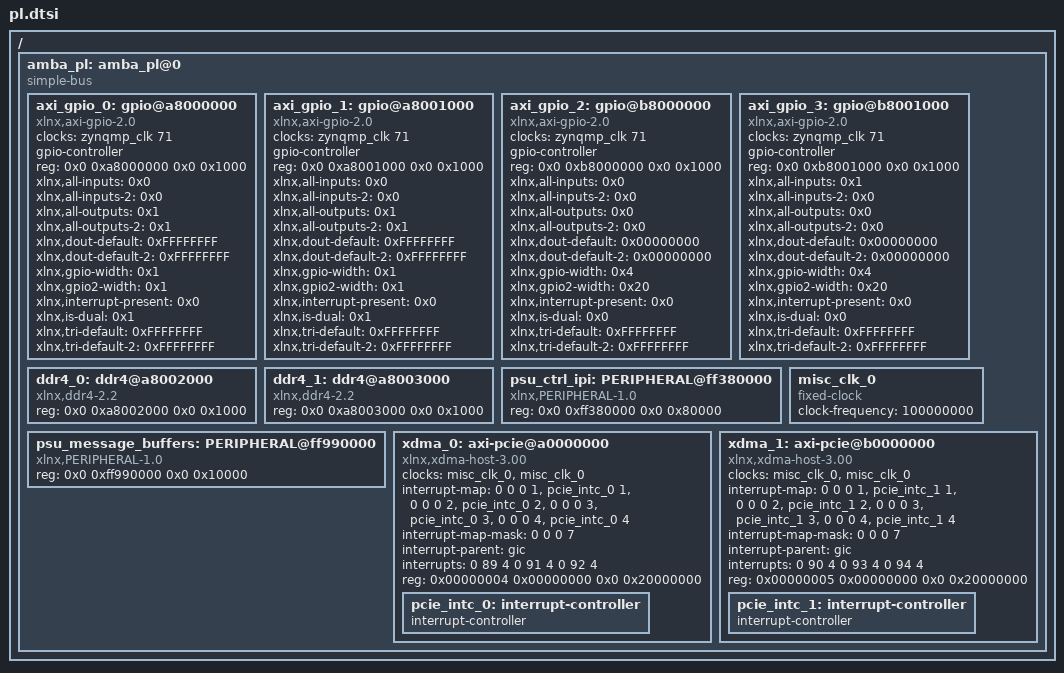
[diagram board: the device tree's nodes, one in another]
/*
 * CAUTION: This file is automatically generated by Xilinx.
 * Version:  
 * Today is: Wed Dec 14 13:36:20 2022
 */


/ {
	amba_pl: amba_pl@0 {
		#address-cells = <2>;
		#size-cells = <2>;
		compatible = "simple-bus";
		ranges ;
		axi_gpio_0: gpio@a8000000 {
			#gpio-cells = <3>;
			clock-names = "s_axi_aclk";
			clocks = <&zynqmp_clk 71>;
			compatible = "xlnx,axi-gpio-2.0", "xlnx,xps-gpio-1.00.a";
			gpio-controller ;
			reg = <0x0 0xa8000000 0x0 0x1000>;
			xlnx,all-inputs = <0x0>;
			xlnx,all-inputs-2 = <0x0>;
			xlnx,all-outputs = <0x1>;
			xlnx,all-outputs-2 = <0x1>;
			xlnx,dout-default = <0xFFFFFFFF>;
			xlnx,dout-default-2 = <0xFFFFFFFF>;
			xlnx,gpio-width = <0x1>;
			xlnx,gpio2-width = <0x1>;
			xlnx,interrupt-present = <0x0>;
			xlnx,is-dual = <0x1>;
			xlnx,tri-default = <0xFFFFFFFF>;
			xlnx,tri-default-2 = <0xFFFFFFFF>;
		};
		axi_gpio_1: gpio@a8001000 {
			#gpio-cells = <3>;
			clock-names = "s_axi_aclk";
			clocks = <&zynqmp_clk 71>;
			compatible = "xlnx,axi-gpio-2.0", "xlnx,xps-gpio-1.00.a";
			gpio-controller ;
			reg = <0x0 0xa8001000 0x0 0x1000>;
			xlnx,all-inputs = <0x0>;
			xlnx,all-inputs-2 = <0x0>;
			xlnx,all-outputs = <0x1>;
			xlnx,all-outputs-2 = <0x1>;
			xlnx,dout-default = <0xFFFFFFFF>;
			xlnx,dout-default-2 = <0xFFFFFFFF>;
			xlnx,gpio-width = <0x1>;
			xlnx,gpio2-width = <0x1>;
			xlnx,interrupt-present = <0x0>;
			xlnx,is-dual = <0x1>;
			xlnx,tri-default = <0xFFFFFFFF>;
			xlnx,tri-default-2 = <0xFFFFFFFF>;
		};
		axi_gpio_2: gpio@b8000000 {
			#gpio-cells = <3>;
			clock-names = "s_axi_aclk";
			clocks = <&zynqmp_clk 71>;
			compatible = "xlnx,axi-gpio-2.0", "xlnx,xps-gpio-1.00.a";
			gpio-controller ;
			reg = <0x0 0xb8000000 0x0 0x1000>;
			xlnx,all-inputs = <0x0>;
			xlnx,all-inputs-2 = <0x0>;
			xlnx,all-outputs = <0x0>;
			xlnx,all-outputs-2 = <0x0>;
			xlnx,dout-default = <0x00000000>;
			xlnx,dout-default-2 = <0x00000000>;
			xlnx,gpio-width = <0x4>;
			xlnx,gpio2-width = <0x20>;
			xlnx,interrupt-present = <0x0>;
			xlnx,is-dual = <0x0>;
			xlnx,tri-default = <0xFFFFFFFF>;
			xlnx,tri-default-2 = <0xFFFFFFFF>;
		};
		axi_gpio_3: gpio@b8001000 {
			#gpio-cells = <3>;
			clock-names = "s_axi_aclk";
			clocks = <&zynqmp_clk 71>;
			compatible = "xlnx,axi-gpio-2.0", "xlnx,xps-gpio-1.00.a";
			gpio-controller ;
			reg = <0x0 0xb8001000 0x0 0x1000>;
			xlnx,all-inputs = <0x1>;
			xlnx,all-inputs-2 = <0x0>;
			xlnx,all-outputs = <0x0>;
			xlnx,all-outputs-2 = <0x0>;
			xlnx,dout-default = <0x00000000>;
			xlnx,dout-default-2 = <0x00000000>;
			xlnx,gpio-width = <0x4>;
			xlnx,gpio2-width = <0x20>;
			xlnx,interrupt-present = <0x0>;
			xlnx,is-dual = <0x0>;
			xlnx,tri-default = <0xFFFFFFFF>;
			xlnx,tri-default-2 = <0xFFFFFFFF>;
		};
		ddr4_0: ddr4@a8002000 {
			compatible = "xlnx,ddr4-2.2";
			reg = <0x0 0xa8002000 0x0 0x1000>;
		};
		ddr4_1: ddr4@a8003000 {
			compatible = "xlnx,ddr4-2.2";
			reg = <0x0 0xa8003000 0x0 0x1000>;
		};
		psu_ctrl_ipi: PERIPHERAL@ff380000 {
			compatible = "xlnx,PERIPHERAL-1.0";
			reg = <0x0 0xff380000 0x0 0x80000>;
		};
		psu_message_buffers: PERIPHERAL@ff990000 {
			compatible = "xlnx,PERIPHERAL-1.0";
			reg = <0x0 0xff990000 0x0 0x10000>;
		};
		xdma_0: axi-pcie@a0000000 {
			#address-cells = <3>;
			#interrupt-cells = <1>;
			#size-cells = <2>;
			clock-names = "sys_clk", "sys_clk_gt";
			clocks = <&misc_clk_0>, <&misc_clk_0>;
			compatible = "xlnx,xdma-host-3.00";
			device_type = "pci";
			interrupt-map = <0 0 0 1 &pcie_intc_0 1>, <0 0 0 2 &pcie_intc_0 2>, <0 0 0 3 &pcie_intc_0 3>, <0 0 0 4 &pcie_intc_0 4>;
			interrupt-map-mask = <0 0 0 7>;
			interrupt-names = "misc", "msi0", "msi1";
			interrupt-parent = <&gic>;
			interrupts = <0 89 4 0 91 4 0 92 4>;
			ranges = <0x02000000 0x00000000 0xA0000000 0x0 0xA0000000 0x00000000 0x08000000>;
			reg = <0x00000004 0x00000000 0x0 0x20000000>;
			pcie_intc_0: interrupt-controller {
				#address-cells = <0>;
				#interrupt-cells = <1>;
				interrupt-controller ;
			};
		};
		misc_clk_0: misc_clk_0 {
			#clock-cells = <0>;
			clock-frequency = <100000000>;
			compatible = "fixed-clock";
		};
		xdma_1: axi-pcie@b0000000 {
			#address-cells = <3>;
			#interrupt-cells = <1>;
			#size-cells = <2>;
			clock-names = "sys_clk", "sys_clk_gt";
			clocks = <&misc_clk_0>, <&misc_clk_0>;
			compatible = "xlnx,xdma-host-3.00";
			device_type = "pci";
			interrupt-map = <0 0 0 1 &pcie_intc_1 1>, <0 0 0 2 &pcie_intc_1 2>, <0 0 0 3 &pcie_intc_1 3>, <0 0 0 4 &pcie_intc_1 4>;
			interrupt-map-mask = <0 0 0 7>;
			interrupt-names = "misc", "msi0", "msi1";
			interrupt-parent = <&gic>;
			interrupts = <0 90 4 0 93 4 0 94 4>;
			ranges = <0x02000000 0x00000000 0xB0000000 0x0 0xB0000000 0x00000000 0x08000000>;
			reg = <0x00000005 0x00000000 0x0 0x20000000>;
			pcie_intc_1: interrupt-controller {
				#address-cells = <0>;
				#interrupt-cells = <1>;
				interrupt-controller ;
			};
		};
	};
};
